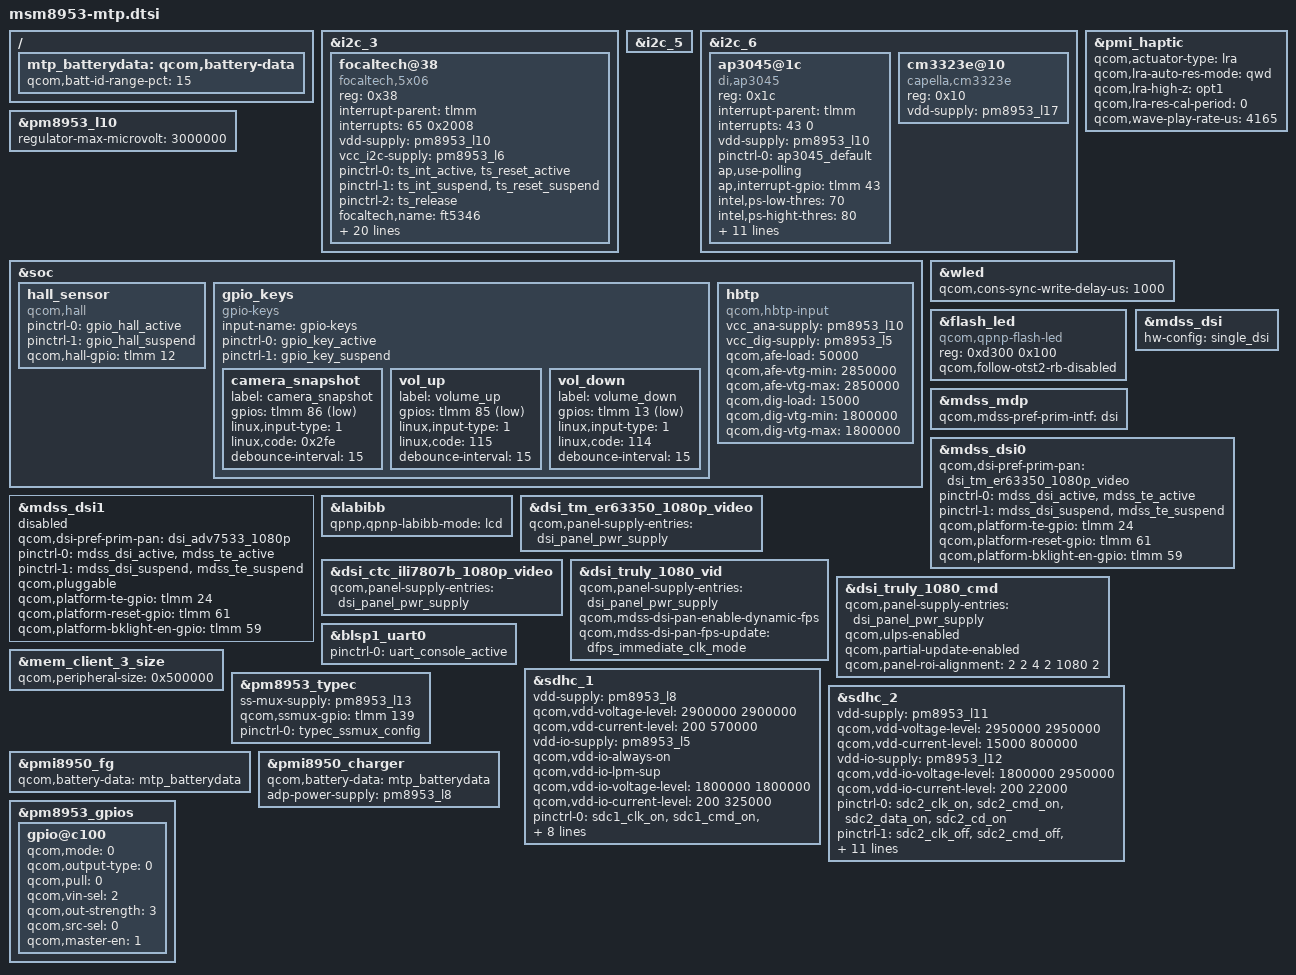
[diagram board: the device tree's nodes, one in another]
/*
 * Copyright (c) 2015-2016, The Linux Foundation. All rights reserved.
 *
 * This program is free software; you can redistribute it and/or modify
 * it under the terms of the GNU General Public License version 2 and
 * only version 2 as published by the Free Software Foundation.
 *
 * This program is distributed in the hope that it will be useful,
 * but WITHOUT ANY WARRANTY; without even the implied warranty of
 * MERCHANTABILITY or FITNESS FOR A PARTICULAR PURPOSE.  See the
 * GNU General Public License for more details.
 */

#include "msm8953-pinctrl.dtsi"
#include "msm8953-audio-mtp.dtsi"
#include "msm8953-camera-sensor-mtp.dtsi"

&i2c_3 { /* BLSP1 QUP3 */
	focaltech@38 {
		compatible = "focaltech,5x06";
		reg = <0x38>;
		interrupt-parent = <&tlmm>;
		interrupts = <65 0x2008>;
		vdd-supply = <&pm8953_l10>;
		vcc_i2c-supply = <&pm8953_l6>;
		/* pins used by touchscreen */
		pinctrl-names = "pmx_ts_active","pmx_ts_suspend","pmx_ts_release";
		pinctrl-0 = <&ts_int_active &ts_reset_active>;
		pinctrl-1 = <&ts_int_suspend &ts_reset_suspend>;
		pinctrl-2 = <&ts_release>;
		focaltech,name = "ft5346";
		focaltech,family-id = <0x54>;
		focaltech,reset-gpio = <&tlmm 64 0x0>;
		focaltech,irq-gpio = <&tlmm 65 0x2008>;
		focaltech,display-coords = <0 0 720 1280>;
		focaltech,panel-coords = <0 0 720 1400>;
		focaltech,button-map= <139 102 158>;
		focaltech,no-force-update;
		focaltech,i2c-pull-up;
		focaltech,group-id = <1>;
		focaltech,hard-reset-delay-ms = <20>;
		focaltech,soft-reset-delay-ms = <200>;
		focaltech,num-max-touches = <5>;
		focaltech,fw-delay-aa-ms = <30>;
		focaltech,fw-delay-55-ms = <30>;
		focaltech,fw-upgrade-id1 = <0x79>;
		focaltech,fw-upgrade-id2 = <0x18>;
		focaltech,fw-delay-readid-ms = <10>;
		focaltech,fw-delay-era-flsh-ms = <2000>;
		focaltech,fw-auto-cal;
		focaltech,ignore-id-check;
	};
};

&i2c_5 { /* BLSP2 QUP1 (NFC) */
/*
	nq@28 {
		compatible = "qcom,nq-nci";
		reg = <0x28>;
		qcom,nq-irq = <&tlmm 17 0x00>;
		qcom,nq-ven = <&tlmm 16 0x00>;
		qcom,nq-firm = <&tlmm 62 0x00>;
		qcom,nq-clkreq = <&pm8953_gpios 2 0x00>;
		interrupt-parent = <&tlmm>;
		qcom,clk-src = "BBCLK2";
		interrupts = <17 0>;
		interrupt-names = "nfc_irq";
		pinctrl-names = "nfc_active", "nfc_suspend";
		pinctrl-0 = <&nfc_int_active &nfc_disable_active>;
		pinctrl-1 = <&nfc_int_suspend &nfc_disable_suspend>;
		clocks = <&clock_gcc clk_bb_clk2_pin>;
		clock-names = "ref_clk";
	};
*/
};

&i2c_6 { /* BLSP2 QUP2 */
	ap3045@1c{ 
		compatible = "di,ap3045";
		reg = <0x1c>;
		interrupt-parent = <&tlmm>;
		interrupts = <43 0>;
		vdd-supply = <&pm8953_l10>;
		//vcc_i2c-supply = <&pm8950_l6>;
		pinctrl-names = "default";
		pinctrl-0 = <&ap3045_default>;
		ap,use-polling;
		ap,interrupt-gpio = <&tlmm 43 0>;
		intel,ps-low-thres = < 70 >;
		intel,ps-hight-thres = < 80 >;
		intel,als-time = <0x10>;		
		intel,als-persis-time = <0x0f>;
		intel,int-ctrl = <0xA8>;
		intel,ps-gain = < 0x40 >; 
		intel,ps-led-control = <0x20>;  /* 33T */
		intel,ps-time = <0x01>;  
		intel,als-gain = < 0x06 >; /* 0:full */
		pm,class-name = "ap3045_class";
		pm,user-name = "ext_proximity_sensor";
		pm,state-D0 = "enable";
		pm,state-D3 = "disable";
		
	};

	cm3323e@10{
		compatible = "capella,cm3323e";
		reg = <0x10>;
		vdd-supply = <&pm8953_l17>;
	};
};

&pm8953_l10 {
	regulator-max-microvolt = <3000000>;
};

&soc {
	hall_sensor {
		compatible = "qcom,hall";
		pinctrl-names = "hall_gpio_high","hall_gpio_low";
		pinctrl-0 = <&gpio_hall_active>;
		pinctrl-1 = <&gpio_hall_suspend>;
		qcom,hall-gpio = <&tlmm 12 0x0>;
	};

	gpio_keys {
		compatible = "gpio-keys";
		input-name = "gpio-keys";
		pinctrl-names = "tlmm_gpio_key_active","tlmm_gpio_key_suspend";
		pinctrl-0 = <&gpio_key_active>;
		pinctrl-1 = <&gpio_key_suspend>;

/* <ASUS_Lotta_Lu-2016/02/29> Note this beacuse because the gpio 87 is not for camera_focus ++++
		camera_focus {
			label = "camera_focus";
			gpios = <&tlmm 87 0x1>;
			linux,input-type = <1>;
			linux,code = <0x210>;
			debounce-interval = <15>;
		};
*/

		camera_snapshot {
			label = "camera_snapshot";
			gpios = <&tlmm 86 0x1>;
			linux,input-type = <1>;
			linux,code = <0x2fe>;
			debounce-interval = <15>;
		};

		vol_up {
			label = "volume_up";
			gpios = <&tlmm 85 0x1>;
			linux,input-type = <1>;
			linux,code = <115>;
			debounce-interval = <15>;
		};
//<ASUS_Hank2_Liu_20160217 Porting Volume Down Key> ++++++
		vol_down {
			label = "volume_down";
			gpios = <&tlmm 13 0x1>;
			linux,input-type = <1>;
			linux,code = <114>;
			debounce-interval = <15>;
		};
//<ASUS_Hank2_Liu_20160217 Porting Volume Down Key> ------
	};

	hbtp {
		compatible = "qcom,hbtp-input";
		vcc_ana-supply = <&pm8953_l10>;
		vcc_dig-supply = <&pm8953_l5>;
		qcom,afe-load = <50000>;
		qcom,afe-vtg-min = <2850000>;
		qcom,afe-vtg-max = <2850000>;
		qcom,dig-load = <15000>;
		qcom,dig-vtg-min = <1800000>;
		qcom,dig-vtg-max = <1800000>;
	};
};

&pmi_haptic{
	qcom,actuator-type = "lra";
	qcom,lra-auto-res-mode="qwd";
	qcom,lra-high-z="opt1";
	qcom,lra-res-cal-period = <0>;
	qcom,wave-play-rate-us = <4165>;
};

&wled {
	qcom,cons-sync-write-delay-us = <1000>;
};

&flash_led {
	compatible = "qcom,qpnp-flash-led";
	reg = <0xd300 0x100>;
	qcom,follow-otst2-rb-disabled;
};

#include "msm8953-mdss-panels.dtsi"

&mdss_mdp {
	qcom,mdss-pref-prim-intf = "dsi";
};

&mdss_dsi {
	hw-config = "single_dsi";
};

&mdss_dsi0 {
	qcom,dsi-pref-prim-pan = <&dsi_tm_er63350_1080p_video>;
	pinctrl-names = "mdss_default", "mdss_sleep";
	pinctrl-0 = <&mdss_dsi_active &mdss_te_active>;
	pinctrl-1 = <&mdss_dsi_suspend &mdss_te_suspend>;

	qcom,platform-te-gpio = <&tlmm 24 0>;
	qcom,platform-reset-gpio = <&tlmm 61 0>;
	qcom,platform-bklight-en-gpio = <&tlmm 59 0>;
};

&mdss_dsi1 {
	status = "disabled";
	qcom,dsi-pref-prim-pan = <&dsi_adv7533_1080p>;
	pinctrl-names = "mdss_default", "mdss_sleep";
	pinctrl-0 = <&mdss_dsi_active &mdss_te_active>;
	pinctrl-1 = <&mdss_dsi_suspend &mdss_te_suspend>;

	qcom,pluggable;
	qcom,platform-te-gpio = <&tlmm 24 0>;
	qcom,platform-reset-gpio = <&tlmm 61 0>;
	qcom,platform-bklight-en-gpio = <&tlmm 59 0>;
};

&labibb {
	status = "ok";
	qpnp,qpnp-labibb-mode = "lcd";
};

//<ASUS_Hank2_Liu_20160217 Bring up Panel in Kernel> ++++++
&dsi_tm_er63350_1080p_video {
	qcom,panel-supply-entries = <&dsi_panel_pwr_supply>;
};

&dsi_ctc_ili7807b_1080p_video {
	qcom,panel-supply-entries = <&dsi_panel_pwr_supply>;
};
//<ASUS_Hank2_Liu_20160217 Bring up Panel in Kernel> ------

&dsi_truly_1080_vid {
	qcom,panel-supply-entries = <&dsi_panel_pwr_supply>;
	qcom,mdss-dsi-pan-enable-dynamic-fps;
	qcom,mdss-dsi-pan-fps-update = "dfps_immediate_clk_mode";
};

&dsi_truly_1080_cmd {
	qcom,panel-supply-entries = <&dsi_panel_pwr_supply>;
	qcom,ulps-enabled;
	qcom,partial-update-enabled;
	qcom,panel-roi-alignment = <2 2 4 2 1080 2>;
};

&blsp1_uart0 {
	status = "ok";
	pinctrl-names = "default";
	pinctrl-0 = <&uart_console_active>;
};

&mem_client_3_size {
	qcom,peripheral-size = <0x500000>;
};

&sdhc_1 {
	/* device core power supply */
	vdd-supply = <&pm8953_l8>;
	qcom,vdd-voltage-level = <2900000 2900000>;
	qcom,vdd-current-level = <200 570000>;

	/* device communication power supply */
	vdd-io-supply = <&pm8953_l5>;
	qcom,vdd-io-always-on;
	qcom,vdd-io-lpm-sup;
	qcom,vdd-io-voltage-level = <1800000 1800000>;
	qcom,vdd-io-current-level = <200 325000>;

	pinctrl-names = "active", "sleep";
	pinctrl-0 = <&sdc1_clk_on &sdc1_cmd_on &sdc1_data_on  &sdc1_rclk_on>;
	pinctrl-1 = <&sdc1_clk_off &sdc1_cmd_off &sdc1_data_off &sdc1_rclk_off>;

	qcom,clk-rates = <400000 20000000 25000000 50000000 100000000 192000000
								384000000>;
	qcom,nonremovable;
	qcom,bus-speed-mode = "HS400_1p8v", "HS200_1p8v", "DDR_1p8v";

	status = "ok";
};

&sdhc_2 {
	/* device core power supply */
	vdd-supply = <&pm8953_l11>;
	qcom,vdd-voltage-level = <2950000 2950000>;
	qcom,vdd-current-level = <15000 800000>;

	/* device communication power supply */
	vdd-io-supply = <&pm8953_l12>;
	qcom,vdd-io-voltage-level = <1800000 2950000>;
	qcom,vdd-io-current-level = <200 22000>;

	pinctrl-names = "active", "sleep";
	pinctrl-0 = <&sdc2_clk_on &sdc2_cmd_on &sdc2_data_on &sdc2_cd_on>;
	pinctrl-1 = <&sdc2_clk_off &sdc2_cmd_off &sdc2_data_off>;

	#address-cells = <0>;
	interrupt-parent = <&sdhc_2>;
	interrupts = <0 1 2>;
	#interrupt-cells = <1>;
	interrupt-map-mask = <0xffffffff>;
	interrupt-map = <0 &intc 0 125 0
		1 &intc 0 221 0
		2 &tlmm 133 0>;
	interrupt-names = "hc_irq", "pwr_irq", "status_irq";
	cd-gpios = <&tlmm 133 0x1>;

	qcom,clk-rates = <400000 20000000 25000000 50000000 100000000
								200000000>;
	qcom,bus-speed-mode = "SDR12", "SDR25", "SDR50", "DDR50", "SDR104";

	status = "ok";
};

&pm8953_typec {
	ss-mux-supply = <&pm8953_l13>;
	qcom,ssmux-gpio = <&tlmm 139 GPIO_ACTIVE_HIGH>;
	pinctrl-names = "default";
	pinctrl-0 = <&typec_ssmux_config>;
};

/{
	mtp_batterydata: qcom,battery-data {
		qcom,batt-id-range-pct = <15>;
		#include "batterydata-itech-3000mah.dtsi"
		#include "batterydata-ascent-3450mAh.dtsi"
	};
};

&pmi8950_fg {
	qcom,battery-data = <&mtp_batterydata>;
};

&pmi8950_charger {
	qcom,battery-data = <&mtp_batterydata>;
	adp-power-supply = <&pm8953_l8>;
	//qcom,chg-led-sw-controls;
	//qcom,chg-led-support;
	//qcom,external-typec;
	//qcom,typec-psy-name = "typec";
};

&pm8953_gpios {
	/* GPIO 2 (NFC_CLK_REQ) */
	gpio@c100 {
		qcom,mode = <0>;
		qcom,output-type = <0>;
		qcom,pull = <0>;
		qcom,vin-sel = <2>;
		qcom,out-strength = <3>;
		qcom,src-sel = <0>;
		qcom,master-en = <1>;
		status = "okay";
	};
};
